# APM32F030 register map
File version: 1.0
Registers are 32-bit, read-write, reset 0x0 unless marked. A register's access mark holds for its fields unless they carry their own. Offsets are from the block's base; [hi:lo] are bit positions; {n}, {i} and the like mark numbered series.

## SYSCFG — System configuration controller
Base 0x40010000
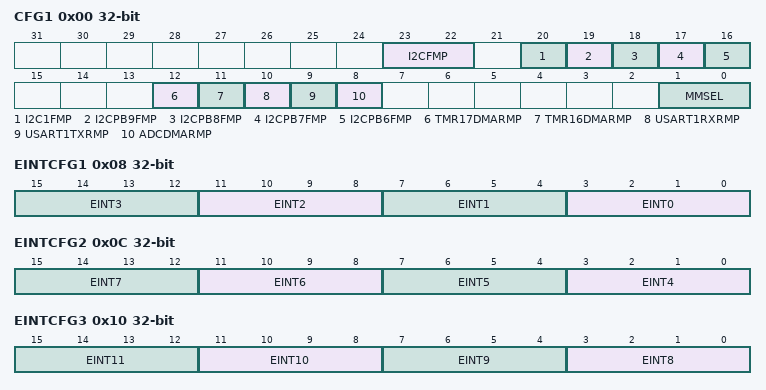
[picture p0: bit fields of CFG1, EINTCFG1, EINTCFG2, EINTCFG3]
0x00 CFG1 — configuration register 1
  [23:22] I2CFMP — FM+ driving capability activation for I2C1
  [20] I2C1FMP — FM+ driving capability activation for I2C1
  [19] I2CPB9FMP — Fast Mode Plus (FM+) driving capability activation bits.
  [18] I2CPB8FMP — Fast Mode Plus (FM+) driving capability activation bits.
  [17] I2CPB7FMP — Fast Mode Plus (FM+) driving capability activation bits.
  [16] I2CPB6FMP — Fast Mode Plus (FM plus) driving capability activation bits.
  [12] TMR17DMARMP — TMR17 DMA request remapping bit
  [11] TMR16DMARMP — TMR16 DMA request remapping bit
  [10] USART1RXRMP — USART1_RX DMA request remapping bit
  [9] USART1TXRMP — USART1_TX DMA remapping bit
  [8] ADCDMARMP — ADC DMA remapping bit
  [1:0] MMSEL — Memory mapping selection bits
0x08 EINTCFG1 — external interrupt configuration register 1
  [4n+3:4n] EINT{n} (n=0..3) — EINT {n} configuration bits
0x0C EINTCFG2 — external interrupt configuration register 2
  [4n-13:4n-16] EINT{n} (n=4..7) — EINT {n} configuration bits
0x10 EINTCFG3 — external interrupt configuration register 3
  [4n-29:4n-32] EINT{n} (n=8..11) — EINT {n} configuration bits
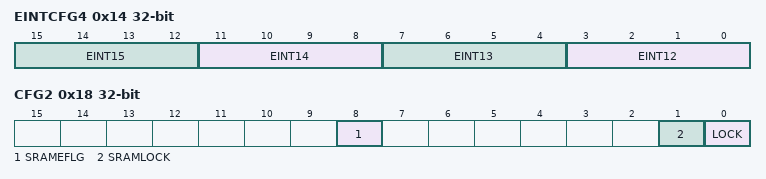
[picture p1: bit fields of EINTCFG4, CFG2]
0x14 EINTCFG4 — external interrupt configuration register 4
  [4n-45:4n-48] EINT{n} (n=12..15) — EINT {n} configuration bits
0x18 CFG2 — configuration register 2
  [8] SRAMEFLG — SRAM parity error flag
  [1] SRAMLOCK — SRAM parity lock bit
  [0] LOCK — Cortex-M0 Hardfault enable bit

## ADC — Analog-to-digital converter
Base 0x40012400
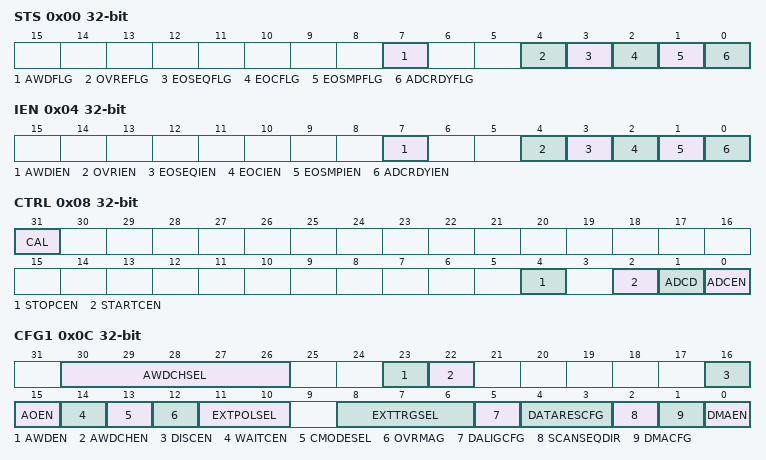
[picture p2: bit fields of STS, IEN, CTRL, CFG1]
0x00 STS — interrupt and status register
  [7] AWDFLG — Analog watchdog flag
  [4] OVREFLG — ADC overrun flag
  [3] EOSEQFLG — End of sequence flag
  [2] EOCFLG — End of conversion flag
  [1] EOSMPFLG — End of sampling flag
  [0] ADCRDYFLG — ADC ready flag
0x04 IEN — interrupt enable register
  [7] AWDIEN — Analog watchdog interrupt enable
  [4] OVRIEN — Overrun interrupt enable
  [3] EOSEQIEN — End of conversion sequence interrupt enable
  [2] EOCIEN — End of conversion interrupt enable
  [1] EOSMPIEN — End of sampling flag interrupt enable
  [0] ADCRDYIEN — ADC ready interrupt enable
0x08 CTRL — control register
  [31] CAL — ADC calibration
  [4] STOPCEN — ADC stop conversion command
  [2] STARTCEN — ADC start conversion command
  [1] ADCD — ADC disable command
  [0] ADCEN — ADC enable command
0x0C CFG1 — configuration register 1
  [30:26] AWDCHSEL — Analog watchdog channel selection
  [23] AWDEN — Analog watchdog enable
  [22] AWDCHEN — Enable the watchdog on a single channel or on all channels
  [16] DISCEN — Discontinuous mode
  [15] AOEN — Auto-off mode
  [14] WAITCEN — Auto-delayed conversion mode
  [13] CMODESEL — Single / continuous conversion mode
  [12] OVRMAG — Overrun management mode
  [11:10] EXTPOLSEL — External trigger enable and polarity selection
  [8:6] EXTTRGSEL — External trigger selection
  [5] DALIGCFG — Data alignment
  [4:3] DATARESCFG — Data resolution
  [2] SCANSEQDIR — Scan sequence direction
  [1] DMACFG — Direct memery access configuration
  [0] DMAEN — Direct memory access enable
0x10 CFG2 — configuration register 2
  [31:30] CLKCFG — ADC clock mode
0x14 SMPTIM — sampling time register
  [2:0] SMPCYCSEL — Sampling time selection
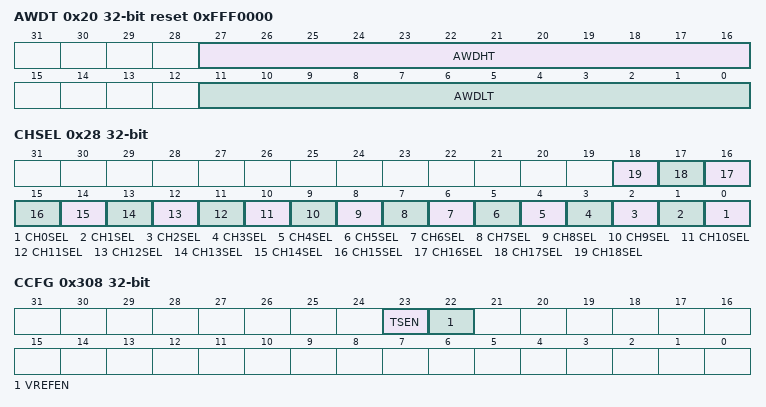
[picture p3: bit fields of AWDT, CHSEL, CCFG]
0x20 AWDT reset 0xFFF0000 — watchdog threshold register
  [27:16] AWDHT — Analog watchdog higher threshold
  [11:0] AWDLT — Analog watchdog lower threshold
0x28 CHSEL — channel selection register
  [n] CH{n}SEL (n=0..18) — Channel-{n} selection
0x40 DATA ro
  [15:0] CDATA — Converted data
0x308 CCFG — common configuration register
  [23] TSEN — Temperature Sensor Enable
  [22] VREFEN — Temperature sensor and VREFINT enable

## USART1 — Universal synchronous asynchronous receiver transmitter
Base 0x40013800
Same registers: USART2 0x40004400, USART3 0x40004800, USART4 0x40004C00, USART5 0x40005000, USART6 0x40011400
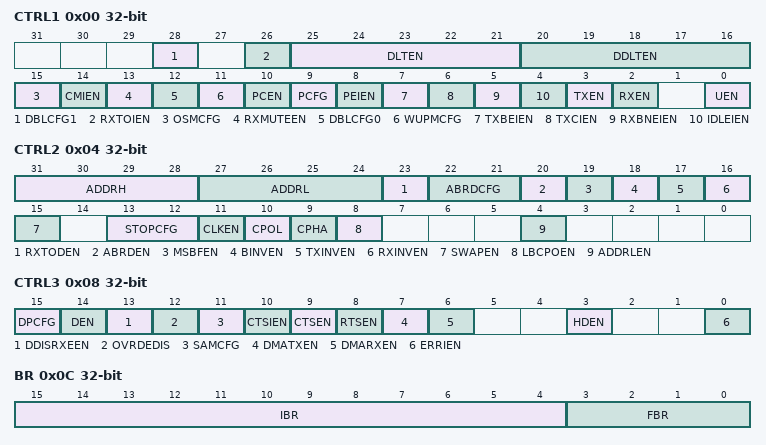
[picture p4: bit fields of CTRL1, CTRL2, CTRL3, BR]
0x00 CTRL1 — Control register 1
  [28] DBLCFG1 — Word length
  [26] RXTOIEN — Receiver timeout interrupt enable
  [25:21] DLTEN — Driver Enable assertion time
  [20:16] DDLTEN — Driver Enable deassertion time
  [15] OSMCFG — Oversampling mode
  [14] CMIEN — Character match interrupt enable
  [13] RXMUTEEN — Mute mode enable
  [12] DBLCFG0 — Word length
  [11] WUPMCFG — Receiver wakeup method
  [10] PCEN — Parity control enable
  [9] PCFG — Parity selection
  [8] PEIEN — PE interrupt enable
  [7] TXBEIEN — interrupt enable
  [6] TXCIEN — Transmission complete interrupt enable
  [5] RXBNEIEN — RXNE interrupt enable
  [4] IDLEIEN — IDLE interrupt enable
  [3] TXEN — Transmitter enable
  [2] RXEN — Receiver enable
  [0] UEN — USART enable
0x04 CTRL2 — Control register 2
  [31:28] ADDRH — Address of the USART node
  [27:24] ADDRL — Address of the USART node
  [23] RXTODEN — Receiver timeout enable
  [22:21] ABRDCFG — Auto baud rate mode
  [20] ABRDEN — Auto baud rate enable
  [19] MSBFEN — Most significant bit first
  [18] BINVEN — Binary data inversion
  [17] TXINVEN — TX pin active level inversion
  [16] RXINVEN — RX pin active level inversion
  [15] SWAPEN — Swap TX/RX pins
  [13:12] STOPCFG — STOP bits
  [11] CLKEN — Clock enable
  [10] CPOL — Clock polarity
  [9] CPHA — Clock phase
  [8] LBCPOEN — Last bit clock pulse
  [4] ADDRLEN — 7-bit Address Detection/4-bit Address Detection
0x08 CTRL3 — Control register 3
  [15] DPCFG — Driver enable polarity selection
  [14] DEN — Driver enable mode
  [13] DDISRXEEN — DMA Disable on Reception Error
  [12] OVRDEDIS — Overrun Disable
  [11] SAMCFG — One sample bit method enable
  [10] CTSIEN — CTS interrupt enable
  [9] CTSEN — CTS enable
  [8] RTSEN — RTS enable
  [7] DMATXEN — DMA enable transmitter
  [6] DMARXEN — DMA enable receiver
  [3] HDEN — Half-duplex selection
  [0] ERRIEN — Error interrupt enable
0x0C BR — Baud rate register
  [15:4] IBR — mantissa of USARTDIV
  [3:0] FBR — fraction of USARTDIV
0x14 RXTO — Receiver timeout register
  [23:0] RXTO — Receiver timeout value
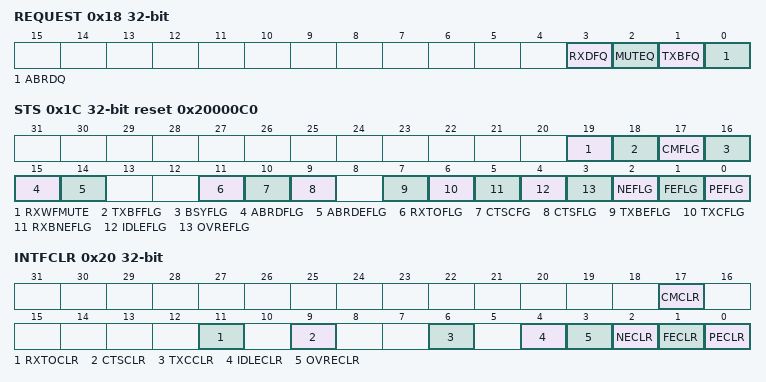
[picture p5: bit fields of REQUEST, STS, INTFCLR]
0x18 REQUEST wo
  [3] RXDFQ — Receive data flush request
  [2] MUTEQ — Mute mode request
  [1] TXBFQ — Send break request
  [0] ABRDQ — Auto baud rate request
0x1C STS ro reset 0x20000C0 — Interrupt & status register
  [19] RXWFMUTE — Receiver wakeup from Mute mode
  [18] TXBFFLG — Send break flag
  [17] CMFLG — character match flag
  [16] BSYFLG — Busy flag
  [15] ABRDFLG — Auto baud rate flag
  [14] ABRDEFLG — Auto baud rate error
  [11] RXTOFLG — Receiver timeout
  [10] CTSCFG — CTS flag
  [9] CTSFLG — CTS interrupt flag
  [7] TXBEFLG — Transmit data register empty
  [6] TXCFLG — Transmission complete
  [5] RXBNEFLG — Read data register not empty
  [4] IDLEFLG — Idle line detected
  [3] OVREFLG — Overrun error
  [2] NEFLG — Noise detected flag
  [1] FEFLG — Framing error
  [0] PEFLG — Parity error
0x20 INTFCLR — Interrupt flag clear register
  [17] CMCLR — Character match clear flag
  [11] RXTOCLR — Receiver timeout clear flag
  [9] CTSCLR — CTS clear flag
  [6] TXCCLR — Transmission complete clear flag
  [4] IDLECLR — Idle line detected clear flag
  [3] OVRECLR — Overrun error clear flag
  [2] NECLR — Noise detected clear flag
  [1] FECLR — Framing error clear flag
  [0] PECLR — Parity error clear flag
0x24 RXDATA ro — Receive data register
  [8:0] RXDATA — Receive data value
0x28 TXDATA — Transmit data register
  [8:0] TXDATA — Transmit data value
